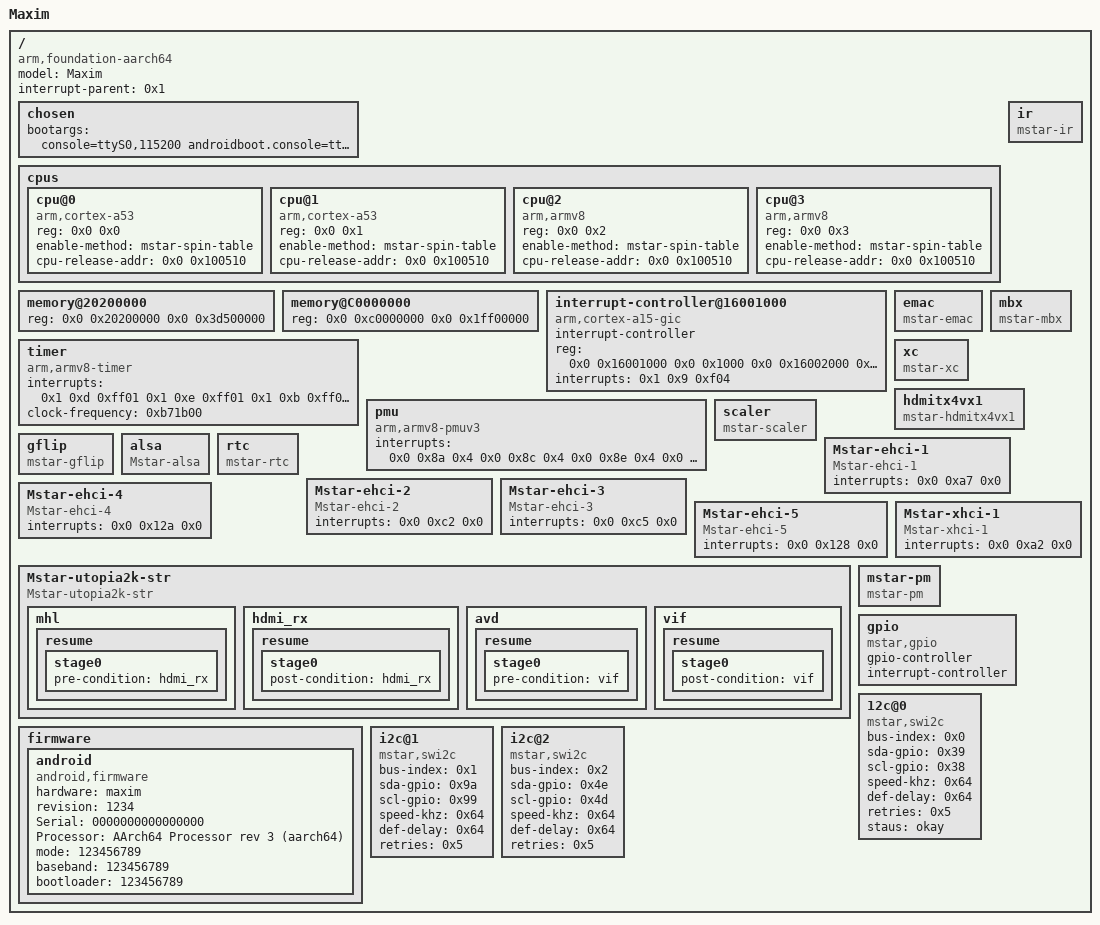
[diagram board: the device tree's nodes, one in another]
#include <../drivers/mstar2/hal/maxim/gpio/dt-bindings/maserati-gpio.h>
#include <dt-bindings/interrupt-controller/arm-gic.h>
#include <dt-bindings/interrupt-controller/irq.h>

/dts-v1/;

/ {
	model = "Maxim";
	compatible = "arm,foundation-aarch64", "arm,maxim";
	interrupt-parent = <0x1>;
	#address-cells = <0x2>;
	#size-cells = <0x2>;

	chosen {
		bootargs = "console=ttyS0,115200 androidboot.console=ttyS0 root=/dev/ram rw rootwait init=/init CORE_DUMP_PATH=/data/core_dump.%%p.gz KDebug=1 delaylogo=true androidboot.selinux=permissive LX_MEM=0x3D500000 LX_MEM2=0xC0000000,0x1FF00000 EMAC_MEM=0x100000 PM51_ADDR=0x20010000 PM51_LEN=0x10000 CMA0=OTHERS,miu=0,hid=23,sz=0x7000000,st=0x11000000 CMA1=VDEC0,miu=0,hid=20,sz=0x3000000,st=0x18000000 CMA2=XC0,miu=0,hid=22,sz=0x6000000,st=0x1b000000 CMA3=OTHERS2,miu=1,hid=24,sz=0xec00000,st=0x0 CMA4=VDEC1,miu=1,hid=19,sz=0x7000000,st=0xec00000 CMA5=RETURN_ENUM,miu=1,hid=25,sz=0x2400000,st=0x15c00000 BOOTLOGO_IN_MBOOT ENV_VAR_OFFSET=0x0 ENV_VAR_SIZE=0x10000 ENV=EMMC SECURITY=ON";
	};

	cpus {
		#address-cells = <0x2>;
		#size-cells = <0x0>;

		cpu@0 {
			compatible = "arm,cortex-a53", "arm,armv8";
			reg = <0x0 0x0>;
			device_type = "cpu";
			enable-method = "mstar-spin-table";
			cpu-release-addr = <0x0 0x100510>;
			linux,phandle = <0x2>;
			phandle = <0x2>;
		};

		cpu@1 {
			compatible = "arm,cortex-a53", "arm,armv8";
			reg = <0x0 0x1>;
			device_type = "cpu";
			enable-method = "mstar-spin-table";
			cpu-release-addr = <0x0 0x100510>;
			linux,phandle = <0x3>;
			phandle = <0x3>;
		};

		cpu@2 {
			device_type = "cpu";
			compatible = "arm,armv8";
			reg = <0x0 0x2>;
			enable-method = "mstar-spin-table";
			cpu-release-addr = <0x0 0x100510>;
		};

		cpu@3 {
			device_type = "cpu";
			compatible = "arm,armv8";
			reg = <0x0 0x3>;
			enable-method = "mstar-spin-table";
			cpu-release-addr = <0x0 0x100510>;
		};
	};

	memory@20200000 {
		device_type = "memory";
		reg = <0x0 0x20200000 0x0 0x3d500000>;
	};

	memory@C0000000 {
		device_type = "memory";
		reg = <0x0 0xc0000000 0x0 0x1ff00000>;
	};

	interrupt-controller@16001000 {
		compatible = "arm,cortex-a15-gic", "arm,cortex-a9-gic";
		#interrupt-cells = <0x3>;
		#address-cells = <0x0>;
		interrupt-controller;
		reg = <0x0 0x16001000 0x0 0x1000 0x0 0x16002000 0x0 0x4000>;
		interrupts = <0x1 0x9 0xf04>;
		linux,phandle = <0x1>;
		phandle = <0x1>;
	};

	timer {
		compatible = "arm,armv8-timer";
		interrupts = <0x1 0xd 0xff01 0x1 0xe 0xff01 0x1 0xb 0xff01 0x1 0xa 0xff01>;
		clock-frequency = <0xb71b00>;
	};

	pmu {
		compatible = "arm,armv8-pmuv3";
		interrupts = <0x0 0x8a 0x4 0x0 0x8c 0x4 0x0 0x8e 0x4 0x0 0x8f 0x4>;
	};

	emac {
		compatible = "mstar-emac";
	};

	ir {
		compatible = "mstar-ir";
	};

	mbx {
		compatible = "mstar-mbx";
	};

	xc {
		compatible = "mstar-xc";
	};

	hdmitx4vx1 {
		compatible = "mstar-hdmitx4vx1";
	};

	scaler {
		compatible = "mstar-scaler";
	};

	gflip {
		compatible = "mstar-gflip";
	};

	alsa {
		compatible = "Mstar-alsa";
	};

	rtc {
		compatible = "mstar-rtc";
	};

	Mstar-ehci-1 {
		compatible = "Mstar-ehci-1";
		interrupts = <0x0 0xa7 0x0>;
	};

	Mstar-ehci-2 {
		compatible = "Mstar-ehci-2";
		interrupts = <0x0 0xc2 0x0>;
	};

	Mstar-ehci-3 {
		compatible = "Mstar-ehci-3";
		interrupts = <0x0 0xc5 0x0>;
	};

	Mstar-ehci-4 {
		compatible = "Mstar-ehci-4";
		interrupts = <0x0 0x12a 0x0>;
	};

	Mstar-ehci-5 {
		compatible = "Mstar-ehci-5";
		interrupts = <0x0 0x128 0x0>;
	};

	Mstar-xhci-1 {
		compatible = "Mstar-xhci-1";
		interrupts = <0x0 0xa2 0x0>;
	};

	Mstar-utopia2k-str {
		compatible = "Mstar-utopia2k-str";

		mhl {

			resume {

				stage0 {
					pre-condition = "hdmi_rx";
				};
			};
		};

		hdmi_rx {

			resume {

				stage0 {
					post-condition = "hdmi_rx";
				};
			};
		};

		avd {

			resume {

				stage0 {
					pre-condition = "vif";
				};
			};
		};

		vif {

			resume {

				stage0 {
					post-condition = "vif";
				};
			};
		};
	};

	mstar-pm {
		compatible = "mstar-pm";
	};

	firmware {

		android {
			compatible = "android,firmware";
			hardware = "maxim";
			revision = "1234";
			Serial = "0000000000000000";
			Processor = "AArch64 Processor rev 3 (aarch64)";
			mode = "123456789";
			baseband = "123456789";
			bootloader = "123456789";
		};
	};

	gpio {
		compatible = "mstar,gpio";
		gpio-controller;
		#gpio-cells = <0x1>;
		interrupt-controller;
		#interrupt-cells = <0x2>;
	};

	12c@0 {
		compatible = "mstar,swi2c";
		bus-index = <0x0>;
		sda-gpio = <0x39>;
		scl-gpio = <0x38>;
		speed-khz = <0x64>;
		def-delay = <0x64>;
		retries = <0x5>;
		staus = "okay";
		#address-cells = <0x1>;
		#size-cells = <0x0>;
	};

	i2c@1 {
		compatible = "mstar,swi2c";
		bus-index = <0x1>;
		sda-gpio = <0x9a>;
		scl-gpio = <0x99>;
		speed-khz = <0x64>;
		def-delay = <0x64>;
		retries = <0x5>;
		status = "okay";
	};

	i2c@2 {
		compatible = "mstar,swi2c";
		bus-index = <0x2>;
		sda-gpio = <0x4e>;
		scl-gpio = <0x4d>;
		speed-khz = <0x64>;
		def-delay = <0x64>;
		retries = <0x5>;
		status = "okay";
	};
};
